# FLASH register map
Vendor: Texas Instruments
Peripheral module from a debugger description file (folder CC26x2x7).
Registers are 32-bit, read-only, reset 0x0 unless marked. A register's access mark holds for its fields unless they carry their own. Offsets are as the file gives them; lines under a group give offsets from that group; [hi:lo] are bit positions; {n}, {i} and the like mark numbered series; 'fields as' and 'values as' point back to an identical list; <NAME> marks a mode.

## FLASH — Flash sub-system registers, includes the Flash Memory Controller (FMC), flash read path, and an integrated Efuse controller and EFUSEROM.
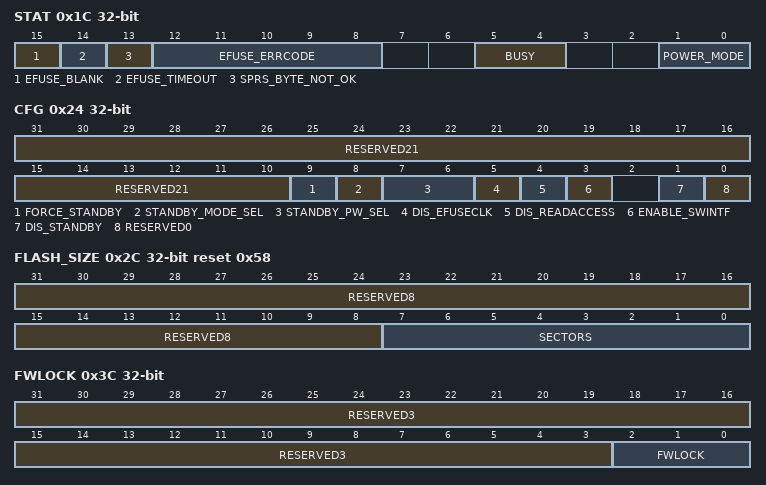
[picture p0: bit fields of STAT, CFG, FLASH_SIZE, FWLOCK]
0x1C STAT — FMC and Efuse Status
  [15] EFUSE_BLANK — Efuse scanning detected if fuse ROM is blank: 0 : Not blank 1 : Blank
  [14] EFUSE_TIMEOUT — Efuse scanning resulted in timeout error. 0 : No Timeout error 1 : Timeout Error
  [13] SPRS_BYTE_NOT_OK — Efuse scanning resulted in scan chain Sparse byte error. 0 : No Sparse error 1 : Sparse Error
  [12:8] EFUSE_ERRCODE — Same as EFUSEERROR.CODE
  [5:4] BUSY — Fast version of the FMC FMSTAT.BUSY bit. This flag is valid immediately after the operation setting it (FMSTAT.BUSY is delayed some cycles) 0 : Not busy 1 : Busy Bit 4 is for the busy state for Bank0 which is at logical address 0x0 Bit 5 for Bank1.
  [1:0] POWER_MODE — Power state of each of the 2 flash bank instances in the flash sub-system. 0 : Active 1 : Low power Bit 0 is for the power state for Bank0 which is at logical address 0x0 Bit 1 for Bank1
0x24 CFG access per field — Internal. Only to be used through TI provided API.
  [31:10] RESERVED21 rw — Internal. Only to be used through TI provided API.
  [9] FORCE_STANDBY rw — Internal. Only to be used through TI provided API.
  [8] STANDBY_MODE_SEL rw — Internal. Only to be used through TI provided API.
  [7:6] STANDBY_PW_SEL rw — Internal. Only to be used through TI provided API.
  [5] DIS_EFUSECLK rw — Internal. Only to be used through TI provided API.
  [4] DIS_READACCESS rw — Internal. Only to be used through TI provided API.
  [3] ENABLE_SWINTF rw — Internal. Only to be used through TI provided API.
  [1] DIS_STANDBY rw — Internal. Only to be used through TI provided API.
  [0] RESERVED0 ro — Internal. Only to be used through TI provided API.
0x2C FLASH_SIZE access per field reset 0x58 — Internal. Only to be used through TI provided API.
  [31:8] RESERVED8 ro — Internal. Only to be used through TI provided API.
  [7:0] SECTORS rw — Internal. Only to be used through TI provided API.
0x3C FWLOCK access per field — Internal. Only to be used through TI provided API.
  [31:3] RESERVED3 ro — Internal. Only to be used through TI provided API.
  [2:0] FWLOCK rw — Internal. Only to be used through TI provided API.
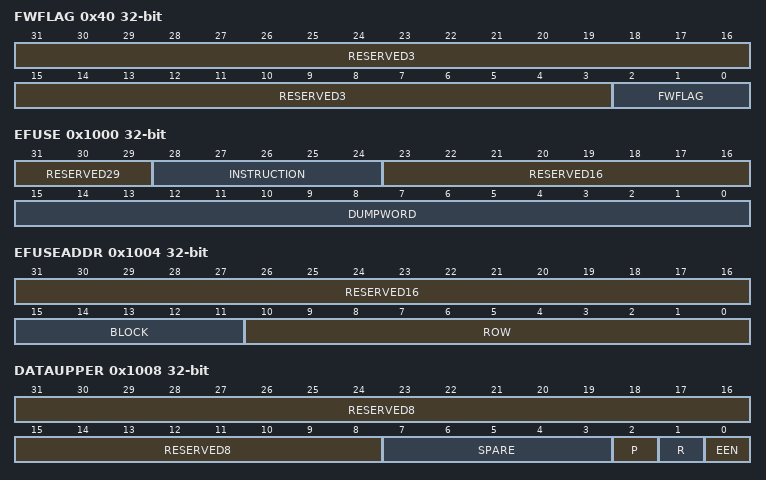
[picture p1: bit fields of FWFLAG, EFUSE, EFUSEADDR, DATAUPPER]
0x40 FWFLAG access per field — Internal. Only to be used through TI provided API.
  [31:3] RESERVED3 ro — Internal. Only to be used through TI provided API.
  [2:0] FWFLAG rw — Internal. Only to be used through TI provided API.
0x1000 EFUSE access per field — Internal. Only to be used through TI provided API.
  [31:29] RESERVED29 ro — Internal. Only to be used through TI provided API.
  [28:24] INSTRUCTION rw — Internal. Only to be used through TI provided API.
  [23:16] RESERVED16 ro — Internal. Only to be used through TI provided API.
  [15:0] DUMPWORD rw — Internal. Only to be used through TI provided API.
0x1004 EFUSEADDR access per field — Internal. Only to be used through TI provided API.
  [31:16] RESERVED16 ro — Internal. Only to be used through TI provided API.
  [15:11] BLOCK rw — Internal. Only to be used through TI provided API.
  [10:0] ROW rw — Internal. Only to be used through TI provided API.
0x1008 DATAUPPER access per field — Internal. Only to be used through TI provided API.
  [31:8] RESERVED8 ro — Internal. Only to be used through TI provided API.
  [7:3] SPARE rw — Internal. Only to be used through TI provided API.
  [2] P rw — Internal. Only to be used through TI provided API.
  [1] R rw — Internal. Only to be used through TI provided API.
  [0] EEN rw — Internal. Only to be used through TI provided API.
0x100C DATALOWER rw — Internal. Only to be used through TI provided API.
  [31:0] DATA
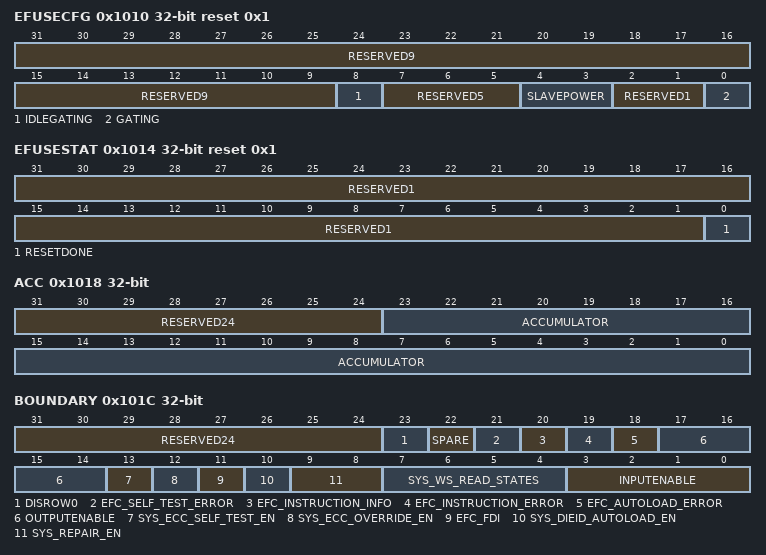
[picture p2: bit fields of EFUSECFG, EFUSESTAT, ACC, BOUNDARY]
0x1010 EFUSECFG access per field reset 0x1 — Internal. Only to be used through TI provided API.
  [31:9] RESERVED9 ro — Internal. Only to be used through TI provided API.
  [8] IDLEGATING rw — Internal. Only to be used through TI provided API.
  [7:5] RESERVED5 ro — Internal. Only to be used through TI provided API.
  [4:3] SLAVEPOWER rw — Internal. Only to be used through TI provided API.
  [2:1] RESERVED1 ro — Internal. Only to be used through TI provided API.
  [0] GATING rw — Internal. Only to be used through TI provided API.
0x1014 EFUSESTAT reset 0x1 — Internal. Only to be used through TI provided API.
  [31:1] RESERVED1 — Internal. Only to be used through TI provided API.
  [0] RESETDONE — Internal. Only to be used through TI provided API.
0x1018 ACC — Internal. Only to be used through TI provided API.
  [31:24] RESERVED24 — Internal. Only to be used through TI provided API.
  [23:0] ACCUMULATOR — Internal. Only to be used through TI provided API.
0x101C BOUNDARY access per field — Internal. Only to be used through TI provided API.
  [31:24] RESERVED24 ro — Internal. Only to be used through TI provided API.
  [23] DISROW0 rw — Internal. Only to be used through TI provided API.
  [22] SPARE rw — Internal. Only to be used through TI provided API.
  [21] EFC_SELF_TEST_ERROR rw — Internal. Only to be used through TI provided API.
  [20] EFC_INSTRUCTION_INFO rw — Internal. Only to be used through TI provided API.
  [19] EFC_INSTRUCTION_ERROR rw — Internal. Only to be used through TI provided API.
  [18] EFC_AUTOLOAD_ERROR rw — Internal. Only to be used through TI provided API.
  [17:14] OUTPUTENABLE rw — Internal. Only to be used through TI provided API.
  [13] SYS_ECC_SELF_TEST_EN rw — Internal. Only to be used through TI provided API.
  [12] SYS_ECC_OVERRIDE_EN rw — Internal. Only to be used through TI provided API.
  [11] EFC_FDI rw — Internal. Only to be used through TI provided API.
  [10] SYS_DIEID_AUTOLOAD_EN rw — Internal. Only to be used through TI provided API.
  [9:8] SYS_REPAIR_EN rw — Internal. Only to be used through TI provided API.
  [7:4] SYS_WS_READ_STATES rw — Internal. Only to be used through TI provided API.
  [3:0] INPUTENABLE rw — Internal. Only to be used through TI provided API.
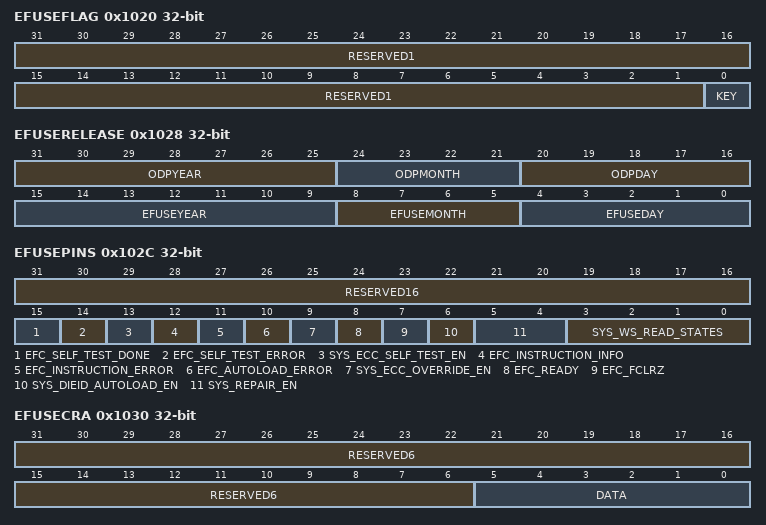
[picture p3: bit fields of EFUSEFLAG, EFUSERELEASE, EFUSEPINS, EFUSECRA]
0x1020 EFUSEFLAG — Internal. Only to be used through TI provided API.
  [31:1] RESERVED1 — Internal. Only to be used through TI provided API.
  [0] KEY — Internal. Only to be used through TI provided API.
0x1024 EFUSEKEY rw — Internal. Only to be used through TI provided API.
  [31:0] CODE
0x1028 EFUSERELEASE — Internal. Only to be used through TI provided API.
  [31:25] ODPYEAR — Internal. Only to be used through TI provided API.
  [24:21] ODPMONTH — Internal. Only to be used through TI provided API.
  [20:16] ODPDAY — Internal. Only to be used through TI provided API.
  [15:9] EFUSEYEAR — Internal. Only to be used through TI provided API.
  [8:5] EFUSEMONTH — Internal. Only to be used through TI provided API.
  [4:0] EFUSEDAY — Internal. Only to be used through TI provided API.
0x102C EFUSEPINS — Internal. Only to be used through TI provided API.
  [31:16] RESERVED16 — Internal. Only to be used through TI provided API.
  [15] EFC_SELF_TEST_DONE — Internal. Only to be used through TI provided API.
  [14] EFC_SELF_TEST_ERROR — Internal. Only to be used through TI provided API.
  [13] SYS_ECC_SELF_TEST_EN — Internal. Only to be used through TI provided API.
  [12] EFC_INSTRUCTION_INFO — Internal. Only to be used through TI provided API.
  [11] EFC_INSTRUCTION_ERROR — Internal. Only to be used through TI provided API.
  [10] EFC_AUTOLOAD_ERROR — Internal. Only to be used through TI provided API.
  [9] SYS_ECC_OVERRIDE_EN — Internal. Only to be used through TI provided API.
  [8] EFC_READY — Internal. Only to be used through TI provided API.
  [7] EFC_FCLRZ — Internal. Only to be used through TI provided API.
  [6] SYS_DIEID_AUTOLOAD_EN — Internal. Only to be used through TI provided API.
  [5:4] SYS_REPAIR_EN — Internal. Only to be used through TI provided API.
  [3:0] SYS_WS_READ_STATES — Internal. Only to be used through TI provided API.
0x1030 EFUSECRA access per field — Internal. Only to be used through TI provided API.
  [31:6] RESERVED6 ro — Internal. Only to be used through TI provided API.
  [5:0] DATA rw — Internal. Only to be used through TI provided API.
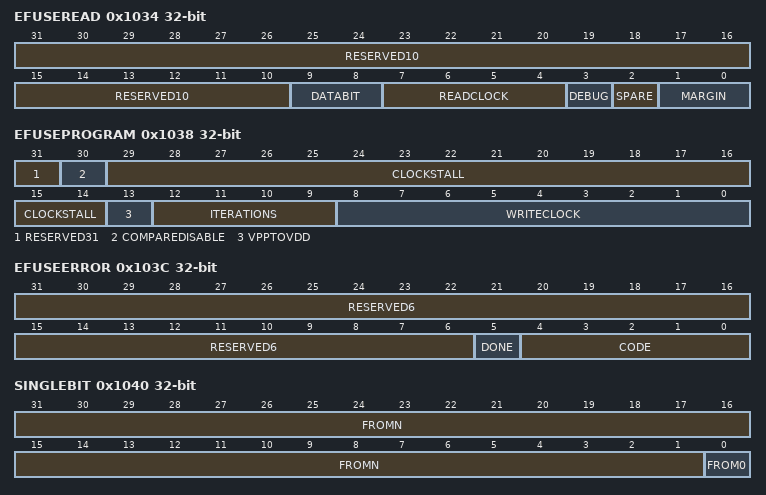
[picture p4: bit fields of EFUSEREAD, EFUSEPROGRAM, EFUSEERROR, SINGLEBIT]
0x1034 EFUSEREAD access per field — Internal. Only to be used through TI provided API.
  [31:10] RESERVED10 ro — Internal. Only to be used through TI provided API.
  [9:8] DATABIT rw — Internal. Only to be used through TI provided API.
  [7:4] READCLOCK rw — Internal. Only to be used through TI provided API.
  [3] DEBUG rw — Internal. Only to be used through TI provided API.
  [2] SPARE rw — Internal. Only to be used through TI provided API.
  [1:0] MARGIN rw — Internal. Only to be used through TI provided API.
0x1038 EFUSEPROGRAM access per field — Internal. Only to be used through TI provided API.
  [31] RESERVED31 ro — Internal. Only to be used through TI provided API.
  [30] COMPAREDISABLE rw — Internal. Only to be used through TI provided API.
  [29:14] CLOCKSTALL rw — Internal. Only to be used through TI provided API.
  [13] VPPTOVDD rw — Internal. Only to be used through TI provided API.
  [12:9] ITERATIONS rw — Internal. Only to be used through TI provided API.
  [8:0] WRITECLOCK rw — Internal. Only to be used through TI provided API.
0x103C EFUSEERROR access per field — Internal. Only to be used through TI provided API.
  [31:6] RESERVED6 ro — Internal. Only to be used through TI provided API.
  [5] DONE rw — Internal. Only to be used through TI provided API.
  [4:0] CODE rw — Internal. Only to be used through TI provided API.
0x1040 SINGLEBIT — Internal. Only to be used through TI provided API.
  [31:1] FROMN — Internal. Only to be used through TI provided API.
  [0] FROM0 — Internal. Only to be used through TI provided API.
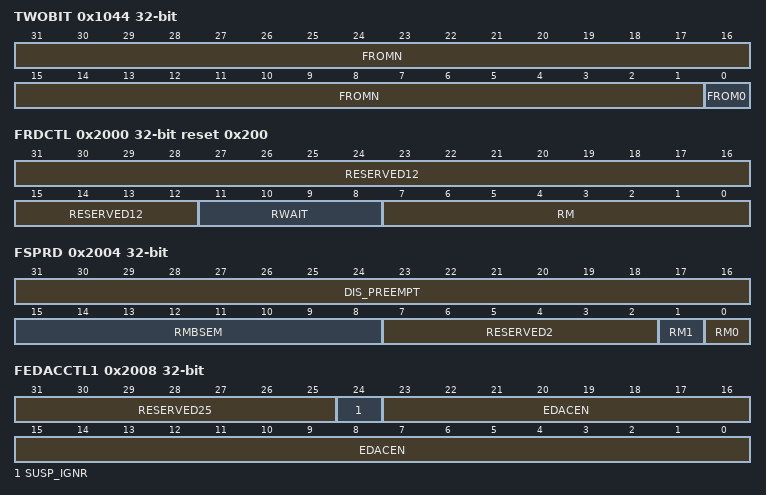
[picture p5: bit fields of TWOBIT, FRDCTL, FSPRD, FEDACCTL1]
0x1044 TWOBIT — Internal. Only to be used through TI provided API.
  fields as SINGLEBIT
0x1048 SELFTESTCYC rw — Internal. Only to be used through TI provided API.
  [31:0] CYCLES
0x104C SELFTESTSIGN rw — Internal. Only to be used through TI provided API.
  [31:0] SIGNATURE
0x2000 FRDCTL access per field reset 0x200 — Internal. Only to be used through TI provided API.
  [31:12] RESERVED12 ro — Internal. Only to be used through TI provided API.
  [11:8] RWAIT rw — Internal. Only to be used through TI provided API.
  [7:0] RM ro — Internal. Only to be used through TI provided API.
0x2004 FSPRD access per field — Internal. Only to be used through TI provided API.
  [31:16] DIS_PREEMPT ro — Internal. Only to be used through TI provided API.
  [15:8] RMBSEM rw — Internal. Only to be used through TI provided API.
  [7:2] RESERVED2 ro — Internal. Only to be used through TI provided API.
  [1] RM1 rw — Internal. Only to be used through TI provided API.
  [0] RM0 rw — Internal. Only to be used through TI provided API.
0x2008 FEDACCTL1 access per field — Internal. Only to be used through TI provided API.
  [31:25] RESERVED25 ro — Internal. Only to be used through TI provided API.
  [24] SUSP_IGNR rw — Internal. Only to be used through TI provided API.
  [23:0] EDACEN ro — Internal. Only to be used through TI provided API.
0x200C FEDACCTL2 — Internal. Only to be used through TI provided API.
  [31:0] SEC_THRESHOLD
0x2010 FCOR_ERR_CNT — Internal. Only to be used through TI provided API.
  [31:0] COR_ERR_CNT
0x2014 FCOR_ERR_ADD — Internal. Only to be used through TI provided API.
0x2018 FCOR_ERR_POS — Internal. Only to be used through TI provided API.
  [31:0] SERR_POS
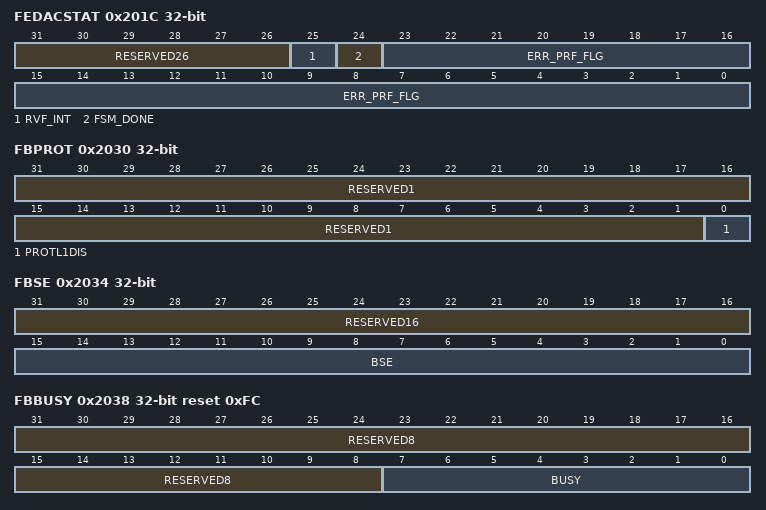
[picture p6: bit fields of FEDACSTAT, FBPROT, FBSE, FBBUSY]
0x201C FEDACSTAT access per field — Internal. Only to be used through TI provided API.
  [31:26] RESERVED26 ro — Internal. Only to be used through TI provided API.
  [25] RVF_INT rw — Internal. Only to be used through TI provided API.
  [24] FSM_DONE rw — Internal. Only to be used through TI provided API.
  [23:0] ERR_PRF_FLG ro — Internal. Only to be used through TI provided API.
0x2020 FUNC_ERR_ADD — Internal. Only to be used through TI provided API.
0x2024 FEDACSDIS — Internal. Only to be used through TI provided API.
  [31:0] SECTORID0
0x2028 FPRIM_ADD_TAG — Internal. Only to be used through TI provided API.
  [31:0] PRIM_ADD_TAG
0x202C FREDU_ADD_TAG — Internal. Only to be used through TI provided API.
  [31:0] REDU_ADD_TAG
0x2030 FBPROT access per field — Internal. Only to be used through TI provided API.
  [31:1] RESERVED1 ro — Internal. Only to be used through TI provided API.
  [0] PROTL1DIS rw — Internal. Only to be used through TI provided API.
0x2034 FBSE access per field — Internal. Only to be used through TI provided API.
  [31:16] RESERVED16 ro — Internal. Only to be used through TI provided API.
  [15:0] BSE rw — Internal. Only to be used through TI provided API.
0x2038 FBBUSY reset 0xFC — Internal. Only to be used through TI provided API.
  [31:8] RESERVED8 — Internal. Only to be used through TI provided API.
  [7:0] BUSY — Internal. Only to be used through TI provided API.
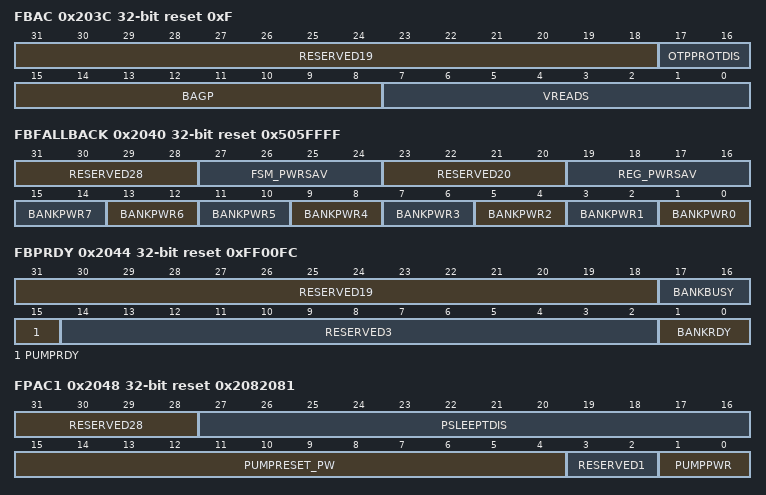
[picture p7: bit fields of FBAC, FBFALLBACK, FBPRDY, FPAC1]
0x203C FBAC access per field reset 0xF — Internal. Only to be used through TI provided API.
  [31:18] RESERVED19 ro — Internal. Only to be used through TI provided API.
  [17:16] OTPPROTDIS rw — Internal. Only to be used through TI provided API.
  [15:8] BAGP rw — Internal. Only to be used through TI provided API.
  [7:0] VREADS rw — Internal. Only to be used through TI provided API.
0x2040 FBFALLBACK access per field reset 0x505FFFF — Internal. Only to be used through TI provided API.
  [31:28] RESERVED28 ro — Internal. Only to be used through TI provided API.
  [27:24] FSM_PWRSAV rw — Internal. Only to be used through TI provided API.
  [23:20] RESERVED20 ro — Internal. Only to be used through TI provided API.
  [19:16] REG_PWRSAV rw — Internal. Only to be used through TI provided API.
  [2n+1:2n] BANKPWR{n} rw (n=0..7) — Internal. Only to be used through TI provided API.
0x2044 FBPRDY reset 0xFF00FC — Internal. Only to be used through TI provided API.
  [31:18] RESERVED19 — Internal. Only to be used through TI provided API.
  [17:16] BANKBUSY — Internal. Only to be used through TI provided API.
  [15] PUMPRDY — Internal. Only to be used through TI provided API.
  [14:2] RESERVED3 — Internal. Only to be used through TI provided API.
  [1:0] BANKRDY — Internal. Only to be used through TI provided API.
0x2048 FPAC1 access per field reset 0x2082081 — Internal. Only to be used through TI provided API.
  [31:28] RESERVED28 ro — Internal. Only to be used through TI provided API.
  [27:16] PSLEEPTDIS rw — Internal. Only to be used through TI provided API.
  [15:4] PUMPRESET_PW rw — Internal. Only to be used through TI provided API.
  [3:2] RESERVED1 ro — Internal. Only to be used through TI provided API.
  [1:0] PUMPPWR rw — Internal. Only to be used through TI provided API.
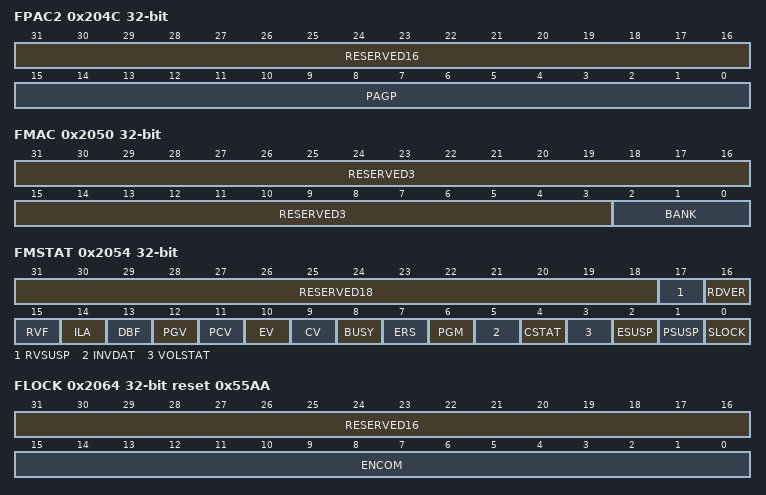
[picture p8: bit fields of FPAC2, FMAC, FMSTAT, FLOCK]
0x204C FPAC2 access per field — Internal. Only to be used through TI provided API.
  [31:16] RESERVED16 ro — Internal. Only to be used through TI provided API.
  [15:0] PAGP rw — Internal. Only to be used through TI provided API.
0x2050 FMAC access per field — Internal. Only to be used through TI provided API.
  [31:3] RESERVED3 ro — Internal. Only to be used through TI provided API.
  [2:0] BANK rw — Internal. Only to be used through TI provided API.
0x2054 FMSTAT — Internal. Only to be used through TI provided API.
  [31:18] RESERVED18 — Internal. Only to be used through TI provided API.
  [17] RVSUSP — Internal. Only to be used through TI provided API.
  [16] RDVER — Internal. Only to be used through TI provided API.
  [15] RVF — Internal. Only to be used through TI provided API.
  [14] ILA — Internal. Only to be used through TI provided API.
  [13] DBF — Internal. Only to be used through TI provided API.
  [12] PGV — Internal. Only to be used through TI provided API.
  [11] PCV — Internal. Only to be used through TI provided API.
  [10] EV — Internal. Only to be used through TI provided API.
  [9] CV — Internal. Only to be used through TI provided API.
  [8] BUSY — Internal. Only to be used through TI provided API.
  [7] ERS — Internal. Only to be used through TI provided API.
  [6] PGM — Internal. Only to be used through TI provided API.
  [5] INVDAT — Internal. Only to be used through TI provided API.
  [4] CSTAT — Internal. Only to be used through TI provided API.
  [3] VOLSTAT — Internal. Only to be used through TI provided API.
  [2] ESUSP — Internal. Only to be used through TI provided API.
  [1] PSUSP — Internal. Only to be used through TI provided API.
  [0] SLOCK — Internal. Only to be used through TI provided API.
0x2058 FEMU_DMSW rw — Internal. Only to be used through TI provided API.
0x205C FEMU_DLSW rw — Internal. Only to be used through TI provided API.
0x2060 FEMU_ECC rw — Internal. Only to be used through TI provided API.
  [31:0] EMU_ECC
0x2064 FLOCK access per field reset 0x55AA — Internal. Only to be used through TI provided API.
  [31:16] RESERVED16 ro — Internal. Only to be used through TI provided API.
  [15:0] ENCOM rw — Internal. Only to be used through TI provided API.
0x2068 FEMU_ADDR rw — Internal. Only to be used through TI provided API.
  [31:0] EMU_ADDR
0x206C FDIAGCTL rw — Internal. Only to be used through TI provided API.
  [31:0] DIAGMODE
0x2070 FRAW_DATAH rw — Internal. Only to be used through TI provided API.
0x2074 FRAW_DATAL rw — Internal. Only to be used through TI provided API.
0x2078 FRAW_ECC rw — Internal. Only to be used through TI provided API.
  [31:0] RAW_ECC
0x207C FPAR_OVR rw — Internal. Only to be used through TI provided API.
  [31:0] DAT_INV_PAR
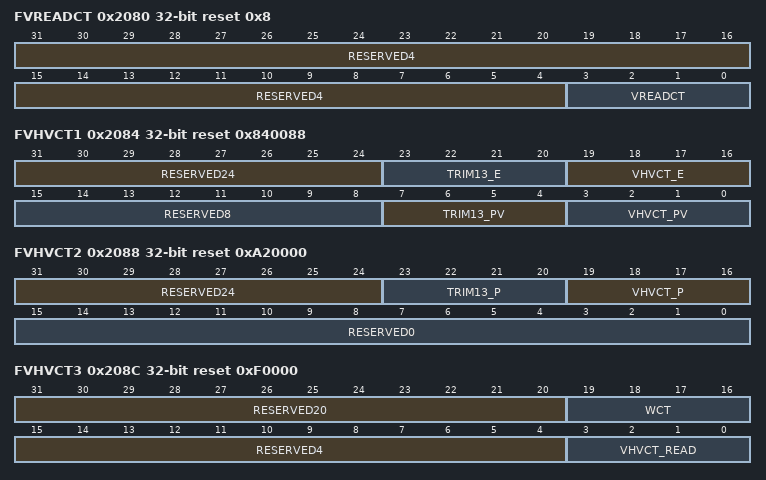
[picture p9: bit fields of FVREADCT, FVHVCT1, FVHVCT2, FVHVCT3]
0x2080 FVREADCT access per field reset 0x8 — Internal. Only to be used through TI provided API.
  [31:4] RESERVED4 ro — Internal. Only to be used through TI provided API.
  [3:0] VREADCT rw — Internal. Only to be used through TI provided API.
0x2084 FVHVCT1 access per field reset 0x840088 — Internal. Only to be used through TI provided API.
  [31:24] RESERVED24 ro — Internal. Only to be used through TI provided API.
  [23:20] TRIM13_E rw — Internal. Only to be used through TI provided API.
  [19:16] VHVCT_E rw — Internal. Only to be used through TI provided API.
  [15:8] RESERVED8 ro — Internal. Only to be used through TI provided API.
  [7:4] TRIM13_PV rw — Internal. Only to be used through TI provided API.
  [3:0] VHVCT_PV rw — Internal. Only to be used through TI provided API.
0x2088 FVHVCT2 access per field reset 0xA20000 — Internal. Only to be used through TI provided API.
  [31:24] RESERVED24 ro — Internal. Only to be used through TI provided API.
  [23:20] TRIM13_P rw — Internal. Only to be used through TI provided API.
  [19:16] VHVCT_P rw — Internal. Only to be used through TI provided API.
  [15:0] RESERVED0 ro — Internal. Only to be used through TI provided API.
0x208C FVHVCT3 access per field reset 0xF0000 — Internal. Only to be used through TI provided API.
  [31:20] RESERVED20 ro — Internal. Only to be used through TI provided API.
  [19:16] WCT rw — Internal. Only to be used through TI provided API.
  [15:4] RESERVED4 ro — Internal. Only to be used through TI provided API.
  [3:0] VHVCT_READ rw — Internal. Only to be used through TI provided API.
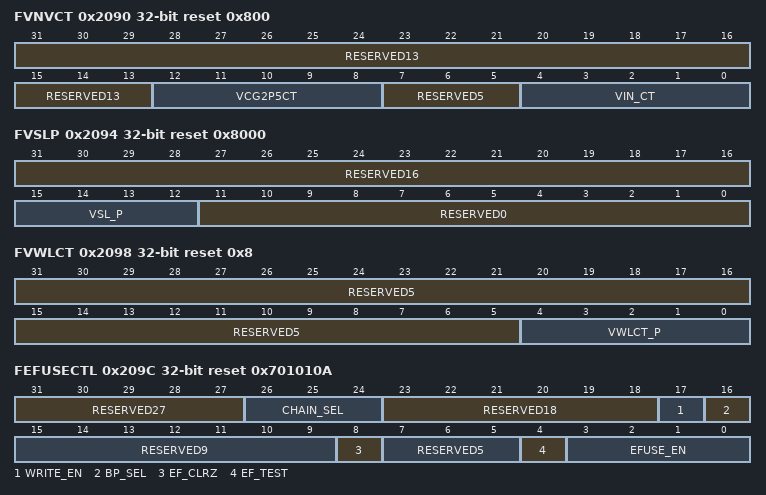
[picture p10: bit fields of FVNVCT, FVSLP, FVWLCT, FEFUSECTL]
0x2090 FVNVCT access per field reset 0x800 — Internal. Only to be used through TI provided API.
  [31:13] RESERVED13 ro — Internal. Only to be used through TI provided API.
  [12:8] VCG2P5CT rw — Internal. Only to be used through TI provided API.
  [7:5] RESERVED5 ro — Internal. Only to be used through TI provided API.
  [4:0] VIN_CT rw — Internal. Only to be used through TI provided API.
0x2094 FVSLP access per field reset 0x8000 — Internal. Only to be used through TI provided API.
  [31:16] RESERVED16 ro — Internal. Only to be used through TI provided API.
  [15:12] VSL_P rw — Internal. Only to be used through TI provided API.
  [11:0] RESERVED0 ro — Internal. Only to be used through TI provided API.
0x2098 FVWLCT access per field reset 0x8 — Internal. Only to be used through TI provided API.
  [31:5] RESERVED5 ro — Internal. Only to be used through TI provided API.
  [4:0] VWLCT_P rw — Internal. Only to be used through TI provided API.
0x209C FEFUSECTL access per field reset 0x701010A — Internal. Only to be used through TI provided API.
  [31:27] RESERVED27 ro — Internal. Only to be used through TI provided API.
  [26:24] CHAIN_SEL rw — Internal. Only to be used through TI provided API.
  [23:18] RESERVED18 ro — Internal. Only to be used through TI provided API.
  [17] WRITE_EN rw — Internal. Only to be used through TI provided API.
  [16] BP_SEL rw — Internal. Only to be used through TI provided API.
  [15:9] RESERVED9 ro — Internal. Only to be used through TI provided API.
  [8] EF_CLRZ rw — Internal. Only to be used through TI provided API.
  [7:5] RESERVED5 ro — Internal. Only to be used through TI provided API.
  [4] EF_TEST rw — Internal. Only to be used through TI provided API.
  [3:0] EFUSE_EN rw — Internal. Only to be used through TI provided API.
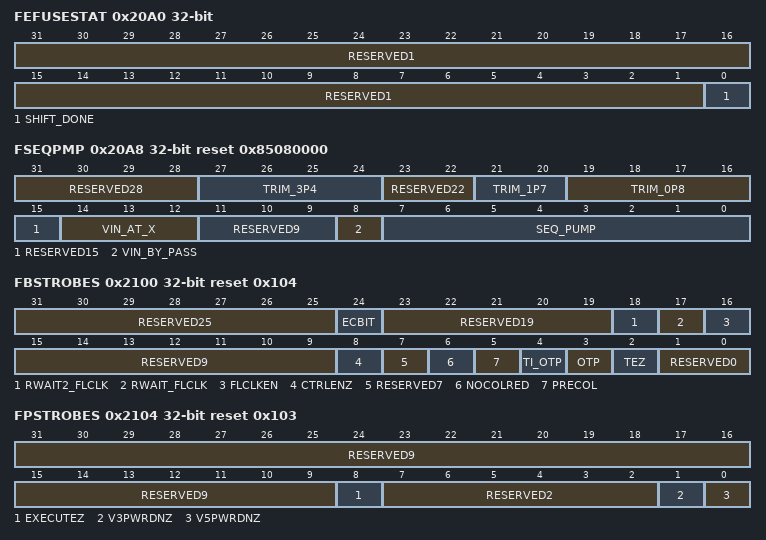
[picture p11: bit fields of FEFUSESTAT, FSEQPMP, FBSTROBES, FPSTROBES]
0x20A0 FEFUSESTAT access per field — Internal. Only to be used through TI provided API.
  [31:1] RESERVED1 ro — Internal. Only to be used through TI provided API.
  [0] SHIFT_DONE rw — Internal. Only to be used through TI provided API.
0x20A4 FEFUSEDATA rw — Internal. Only to be used through TI provided API.
0x20A8 FSEQPMP access per field reset 0x85080000 — Internal. Only to be used through TI provided API.
  [31:28] RESERVED28 rw — Internal. Only to be used through TI provided API.
  [27:24] TRIM_3P4 rw — Internal. Only to be used through TI provided API.
  [23:22] RESERVED22 ro — Internal. Only to be used through TI provided API.
  [21:20] TRIM_1P7 rw — Internal. Only to be used through TI provided API.
  [19:16] TRIM_0P8 rw — Internal. Only to be used through TI provided API.
  [15] RESERVED15 ro — Internal. Only to be used through TI provided API.
  [14:12] VIN_AT_X rw — Internal. Only to be used through TI provided API.
  [11:9] RESERVED9 ro — Internal. Only to be used through TI provided API.
  [8] VIN_BY_PASS rw — Internal. Only to be used through TI provided API.
  [7:0] SEQ_PUMP rw — Internal. Only to be used through TI provided API.
0x20AC FCLKTRIM rw — Internal. Only to be used through TI provided API.
  [31:0] TRIM_EN
0x20B0 ROM_TEST rw — Internal. Only to be used through TI provided API.
  [31:0] ROM_KEY
0x20C0 FEDACSDIS2 rw — Internal. Only to be used through TI provided API.
  [31:0] SECTORID2
0x2100 FBSTROBES access per field reset 0x104 — Internal. Only to be used through TI provided API.
  [31:25] RESERVED25 ro — Internal. Only to be used through TI provided API.
  [24] ECBIT rw — Internal. Only to be used through TI provided API.
  [23:19] RESERVED19 ro — Internal. Only to be used through TI provided API.
  [18] RWAIT2_FLCLK rw — Internal. Only to be used through TI provided API.
  [17] RWAIT_FLCLK rw — Internal. Only to be used through TI provided API.
  [16] FLCLKEN rw — Internal. Only to be used through TI provided API.
  [15:9] RESERVED9 ro — Internal. Only to be used through TI provided API.
  [8] CTRLENZ rw — Internal. Only to be used through TI provided API.
  [7] RESERVED7 ro — Internal. Only to be used through TI provided API.
  [6] NOCOLRED rw — Internal. Only to be used through TI provided API.
  [5] PRECOL rw — Internal. Only to be used through TI provided API.
  [4] TI_OTP rw — Internal. Only to be used through TI provided API.
  [3] OTP rw — Internal. Only to be used through TI provided API.
  [2] TEZ rw — Internal. Only to be used through TI provided API.
  [1:0] RESERVED0 ro — Internal. Only to be used through TI provided API.
0x2104 FPSTROBES access per field reset 0x103 — Internal. Only to be used through TI provided API.
  [31:9] RESERVED9 ro — Internal. Only to be used through TI provided API.
  [8] EXECUTEZ rw — Internal. Only to be used through TI provided API.
  [7:2] RESERVED2 ro — Internal. Only to be used through TI provided API.
  [1] V3PWRDNZ rw — Internal. Only to be used through TI provided API.
  [0] V5PWRDNZ rw — Internal. Only to be used through TI provided API.
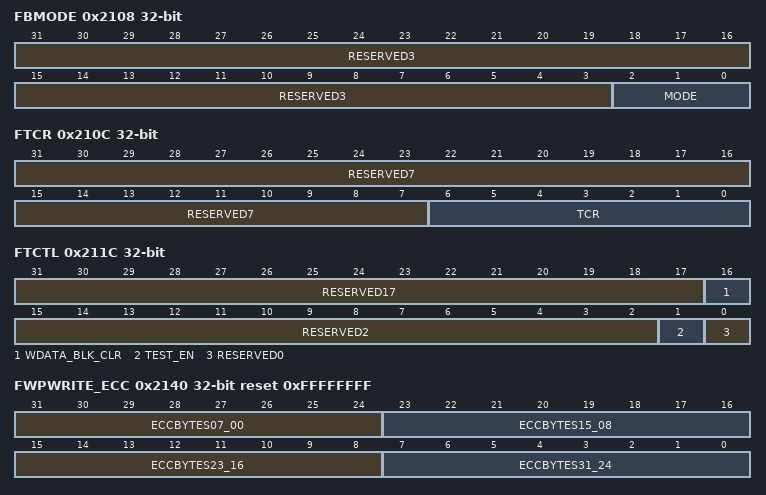
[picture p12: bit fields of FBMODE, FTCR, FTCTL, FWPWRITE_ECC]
0x2108 FBMODE access per field — Internal. Only to be used through TI provided API.
  [31:3] RESERVED3 ro — Internal. Only to be used through TI provided API.
  [2:0] MODE rw — Internal. Only to be used through TI provided API.
0x210C FTCR access per field — Internal. Only to be used through TI provided API.
  [31:7] RESERVED7 ro — Internal. Only to be used through TI provided API.
  [6:0] TCR rw — Internal. Only to be used through TI provided API.
0x2110 FADDR rw — Internal. Only to be used through TI provided API.
0x2114 FPMTCTL — Internal. Only to be used through TI provided API.
  [31:0] ADDR_INCR
0x2118 PBISTCTL — Internal. Only to be used through TI provided API.
  [31:0] PBIST_KEY
0x211C FTCTL access per field — Internal. Only to be used through TI provided API.
  [31:17] RESERVED17 ro — Internal. Only to be used through TI provided API.
  [16] WDATA_BLK_CLR rw — Internal. Only to be used through TI provided API.
  [15:2] RESERVED2 ro — Internal. Only to be used through TI provided API.
  [1] TEST_EN rw — Internal. Only to be used through TI provided API.
  [0] RESERVED0 ro — Internal. Only to be used through TI provided API.
{0x2120+4i} FWPWRITE{i} rw reset 0xFFFFFFFF (i=0..7) — Internal. Only to be used through TI provided API.
0x2140 FWPWRITE_ECC rw reset 0xFFFFFFFF — Internal. Only to be used through TI provided API.
  [31:24] ECCBYTES07_00 — Internal. Only to be used through TI provided API.
  [23:16] ECCBYTES15_08 — Internal. Only to be used through TI provided API.
  [15:8] ECCBYTES23_16 — Internal. Only to be used through TI provided API.
  [7:0] ECCBYTES31_24 — Internal. Only to be used through TI provided API.
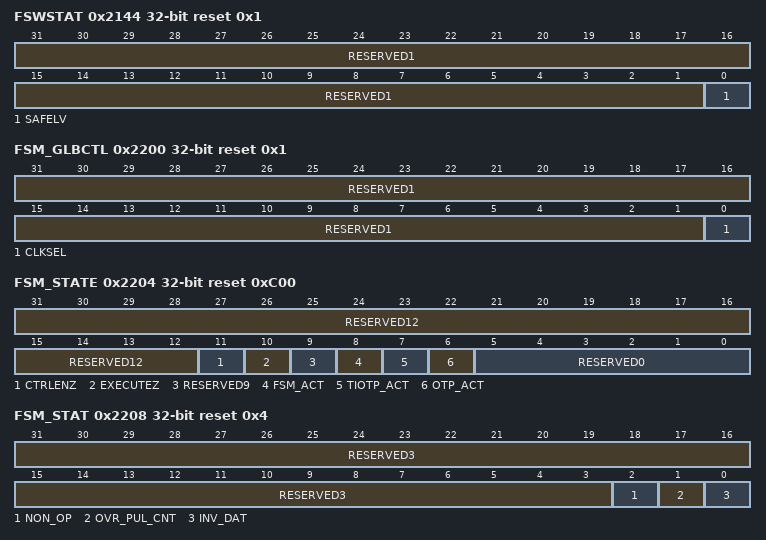
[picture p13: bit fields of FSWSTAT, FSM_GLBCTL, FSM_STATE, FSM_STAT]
0x2144 FSWSTAT reset 0x1 — Internal. Only to be used through TI provided API.
  [31:1] RESERVED1 — Internal. Only to be used through TI provided API.
  [0] SAFELV — Internal. Only to be used through TI provided API.
0x2200 FSM_GLBCTL reset 0x1 — Internal. Only to be used through TI provided API.
  [31:1] RESERVED1 — Internal. Only to be used through TI provided API.
  [0] CLKSEL — Internal. Only to be used through TI provided API.
0x2204 FSM_STATE reset 0xC00 — Internal. Only to be used through TI provided API.
  [31:12] RESERVED12 — Internal. Only to be used through TI provided API.
  [11] CTRLENZ — Internal. Only to be used through TI provided API.
  [10] EXECUTEZ — Internal. Only to be used through TI provided API.
  [9] RESERVED9 — Internal. Only to be used through TI provided API.
  [8] FSM_ACT — Internal. Only to be used through TI provided API.
  [7] TIOTP_ACT — Internal. Only to be used through TI provided API.
  [6] OTP_ACT — Internal. Only to be used through TI provided API.
  [5:0] RESERVED0 — Internal. Only to be used through TI provided API.
0x2208 FSM_STAT reset 0x4 — Internal. Only to be used through TI provided API.
  [31:3] RESERVED3 — Internal. Only to be used through TI provided API.
  [2] NON_OP — Internal. Only to be used through TI provided API.
  [1] OVR_PUL_CNT — Internal. Only to be used through TI provided API.
  [0] INV_DAT — Internal. Only to be used through TI provided API.
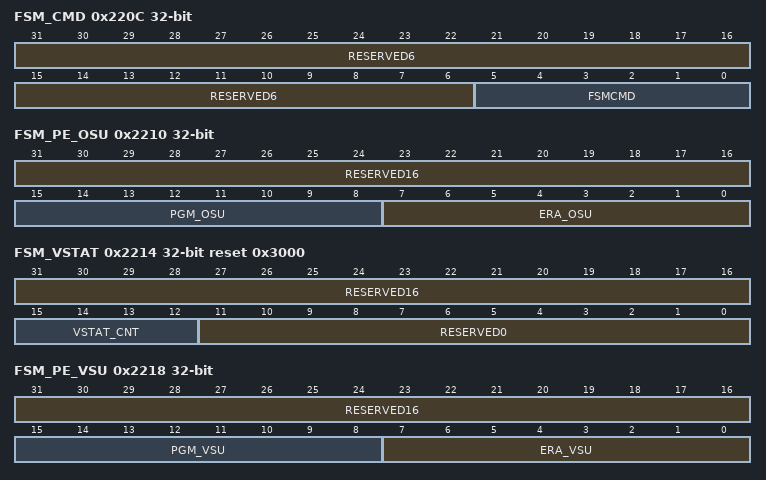
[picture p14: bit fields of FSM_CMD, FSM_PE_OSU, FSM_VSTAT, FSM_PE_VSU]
0x220C FSM_CMD access per field — Internal. Only to be used through TI provided API.
  [31:6] RESERVED6 ro — Internal. Only to be used through TI provided API.
  [5:0] FSMCMD rw — Internal. Only to be used through TI provided API.
0x2210 FSM_PE_OSU access per field — Internal. Only to be used through TI provided API.
  [31:16] RESERVED16 ro — Internal. Only to be used through TI provided API.
  [15:8] PGM_OSU rw — Internal. Only to be used through TI provided API.
  [7:0] ERA_OSU rw — Internal. Only to be used through TI provided API.
0x2214 FSM_VSTAT access per field reset 0x3000 — Internal. Only to be used through TI provided API.
  [31:16] RESERVED16 ro — Internal. Only to be used through TI provided API.
  [15:12] VSTAT_CNT rw — Internal. Only to be used through TI provided API.
  [11:0] RESERVED0 ro — Internal. Only to be used through TI provided API.
0x2218 FSM_PE_VSU access per field — Internal. Only to be used through TI provided API.
  [31:16] RESERVED16 ro — Internal. Only to be used through TI provided API.
  [15:8] PGM_VSU rw — Internal. Only to be used through TI provided API.
  [7:0] ERA_VSU rw — Internal. Only to be used through TI provided API.
0x221C FSM_CMP_VSU access per field — Internal. Only to be used through TI provided API.
  [31:16] RESERVED16 ro — Internal. Only to be used through TI provided API.
  [15:12] ADD_EXZ rw — Internal. Only to be used through TI provided API.
  [11:0] RESERVED0 ro — Internal. Only to be used through TI provided API.
0x2220 FSM_EX_VAL access per field reset 0x301 — Internal. Only to be used through TI provided API.
  [31:16] RESERVED16 ro — Internal. Only to be used through TI provided API.
  [15:8] REP_VSU rw — Internal. Only to be used through TI provided API.
  [7:0] EXE_VALD rw — Internal. Only to be used through TI provided API.
0x2224 FSM_RD_H access per field reset 0x5A — Internal. Only to be used through TI provided API.
  [31:8] RESERVED8 ro — Internal. Only to be used through TI provided API.
  [7:0] RD_H rw — Internal. Only to be used through TI provided API.
0x2228 FSM_P_OH access per field reset 0x100 — Internal. Only to be used through TI provided API.
  [31:16] RESERVED16 ro — Internal. Only to be used through TI provided API.
  [15:8] PGM_OH rw — Internal. Only to be used through TI provided API.
  [7:0] RESERVED0 ro — Internal. Only to be used through TI provided API.
0x222C FSM_ERA_OH access per field reset 0x1 — Internal. Only to be used through TI provided API.
  [31:16] RESERVED16 ro — Internal. Only to be used through TI provided API.
  [15:0] ERA_OH rw — Internal. Only to be used through TI provided API.
0x2230 FSM_SAV_PPUL — Internal. Only to be used through TI provided API.
  [31:12] RESERVED12 — Internal. Only to be used through TI provided API.
  [11:0] SAV_P_PUL — Internal. Only to be used through TI provided API.
0x2234 FSM_PE_VH access per field reset 0x100 — Internal. Only to be used through TI provided API.
  [31:16] RESERVED16 ro — Internal. Only to be used through TI provided API.
  [15:8] PGM_VH rw — Internal. Only to be used through TI provided API.
  [7:0] ERA_VH ro — Internal. Only to be used through TI provided API.
0x2240 FSM_PRG_PW access per field — Internal. Only to be used through TI provided API.
  [31:16] RESERVED16 ro — Internal. Only to be used through TI provided API.
  [15:0] PROG_PUL_WIDTH rw — Internal. Only to be used through TI provided API.
0x2244 FSM_ERA_PW rw — Internal. Only to be used through TI provided API.
0x2254 FSM_SAV_ERA_PUL — Internal. Only to be used through TI provided API.
  [31:12] RESERVED12 — Internal. Only to be used through TI provided API.
  [11:0] SAV_ERA_PUL — Internal. Only to be used through TI provided API.
0x2258 FSM_TIMER — Internal. Only to be used through TI provided API.
0x225C FSM_MODE — Internal. Only to be used through TI provided API.
  [31:20] RESERVED20 — Internal. Only to be used through TI provided API.
  [19:18] RDV_SUBMODE — Internal. Only to be used through TI provided API.
  [17:16] PGM_SUBMODE — Internal. Only to be used through TI provided API.
  [15:14] ERA_SUBMODE — Internal. Only to be used through TI provided API.
  [13:12] SUBMODE — Internal. Only to be used through TI provided API.
  [11:9] SAV_PGM_CMD — Internal. Only to be used through TI provided API.
  [8:6] SAV_ERA_MODE — Internal. Only to be used through TI provided API.
  [5:3] MODE — Internal. Only to be used through TI provided API.
  [2:0] CMD — Internal. Only to be used through TI provided API.
0x2260 FSM_PGM — Internal. Only to be used through TI provided API.
  [31:26] RESERVED26 — Internal. Only to be used through TI provided API.
  [25:23] PGM_BANK — Internal. Only to be used through TI provided API.
  [22:0] PGM_ADDR — Internal. Only to be used through TI provided API.
0x2264 FSM_ERA — Internal. Only to be used through TI provided API.
  [31:26] RESERVED26 — Internal. Only to be used through TI provided API.
  [25:23] ERA_BANK — Internal. Only to be used through TI provided API.
  [22:0] ERA_ADDR — Internal. Only to be used through TI provided API.
0x2268 FSM_PRG_PUL access per field reset 0x40032 — Internal. Only to be used through TI provided API.
  [31:20] RESERVED20 ro — Internal. Only to be used through TI provided API.
  [19:16] BEG_EC_LEVEL rw — Internal. Only to be used through TI provided API.
  [15:12] RESERVED12 ro — Internal. Only to be used through TI provided API.
  [11:0] MAX_PRG_PUL rw — Internal. Only to be used through TI provided API.
0x226C FSM_ERA_PUL access per field reset 0x40BB8 — Internal. Only to be used through TI provided API.
  [31:20] RESERVED20 ro — Internal. Only to be used through TI provided API.
  [19:16] MAX_EC_LEVEL rw — Internal. Only to be used through TI provided API.
  [15:12] RESERVED12 ro — Internal. Only to be used through TI provided API.
  [11:0] MAX_ERA_PUL rw — Internal. Only to be used through TI provided API.
0x2270 FSM_STEP_SIZE access per field — Internal. Only to be used through TI provided API.
  [31:25] RESERVED25 ro — Internal. Only to be used through TI provided API.
  [24:16] EC_STEP_SIZE rw — Internal. Only to be used through TI provided API.
  [15:0] RESERVED0 ro — Internal. Only to be used through TI provided API.
0x2274 FSM_PUL_CNTR — Internal. Only to be used through TI provided API.
  [31:25] RESERVED25 — Internal. Only to be used through TI provided API.
  [24:16] CUR_EC_LEVEL — Internal. Only to be used through TI provided API.
  [15:12] RESERVED12 — Internal. Only to be used through TI provided API.
  [11:0] PUL_CNTR — Internal. Only to be used through TI provided API.
0x2278 FSM_EC_STEP_HEIGHT access per field — Internal. Only to be used through TI provided API.
  [31:4] RESERVED4 ro — Internal. Only to be used through TI provided API.
  [3:0] EC_STEP_HEIGHT rw — Internal. Only to be used through TI provided API.
0x227C FSM_ST_MACHINE access per field reset 0x800500 — Internal. Only to be used through TI provided API.
  [31:24] RESERVED24 ro — Internal. Only to be used through TI provided API.
  [23] DO_PRECOND rw — Internal. Only to be used through TI provided API.
  [22] FSM_INT_EN rw — Internal. Only to be used through TI provided API.
  [21] ALL_BANKS rw — Internal. Only to be used through TI provided API.
  [20] CMPV_ALLOWED rw — Internal. Only to be used through TI provided API.
  [19] RANDOM rw — Internal. Only to be used through TI provided API.
  [18] RV_SEC_EN rw — Internal. Only to be used through TI provided API.
  [17] RV_RES rw — Internal. Only to be used through TI provided API.
  [16] RV_INT_EN rw — Internal. Only to be used through TI provided API.
  [15] RESERVED15 ro — Internal. Only to be used through TI provided API.
  [14] ONE_TIME_GOOD rw — Internal. Only to be used through TI provided API.
  [13:12] RESERVED12 ro — Internal. Only to be used through TI provided API.
  [11] DO_REDU_COL rw — Internal. Only to be used through TI provided API.
  [10:7] DBG_SHORT_ROW rw — Internal. Only to be used through TI provided API.
  [6] RESERVED6 ro — Internal. Only to be used through TI provided API.
  [5] PGM_SEC_COF_EN rw — Internal. Only to be used through TI provided API.
  [4] PREC_STOP_EN rw — Internal. Only to be used through TI provided API.
  [3] DIS_TST_EN rw — Internal. Only to be used through TI provided API.
  [2] CMD_EN rw — Internal. Only to be used through TI provided API.
  [1] INV_DATA rw — Internal. Only to be used through TI provided API.
  [0] OVERRIDE rw — Internal. Only to be used through TI provided API.
0x2280 FSM_FLES access per field — Internal. Only to be used through TI provided API.
  [31:12] RESERVED12 ro — Internal. Only to be used through TI provided API.
  [11:8] BLK_TIOTP rw — Internal. Only to be used through TI provided API.
  [7:0] BLK_OTP rw — Internal. Only to be used through TI provided API.
0x2288 FSM_WR_ENA access per field reset 0x2 — Internal. Only to be used through TI provided API.
  [31:3] RESERVED3 ro — Internal. Only to be used through TI provided API.
  [2:0] WR_ENA rw — Internal. Only to be used through TI provided API.
0x228C FSM_ACC_PP — Internal. Only to be used through TI provided API.
0x2290 FSM_ACC_EP — Internal. Only to be used through TI provided API.
  [31:16] RESERVED16 — Internal. Only to be used through TI provided API.
  [15:0] ACC_EP — Internal. Only to be used through TI provided API.
0x22A0 FSM_ADDR — Internal. Only to be used through TI provided API.
  [31] RESERVED31 — Internal. Only to be used through TI provided API.
  [30:28] BANK — Internal. Only to be used through TI provided API.
  [27:0] CUR_ADDR — Internal. Only to be used through TI provided API.
0x22A4 FSM_SECTOR access per field reset 0xFFFF0000 — Internal. Only to be used through TI provided API.
  [31:16] SECT_ERASED rw — Internal. Only to be used through TI provided API.
  [15:8] FSM_SECTOR_EXTENSION ro — Internal. Only to be used through TI provided API.
  [7:4] SECTOR ro — Internal. Only to be used through TI provided API.
  [3:0] SEC_OUT ro — Internal. Only to be used through TI provided API.
0x22A8 FMC_REV_ID — Internal. Only to be used through TI provided API.
  [31:12] MOD_VERSION — Internal. Only to be used through TI provided API.
  [11:0] CONFIG_CRC — Internal. Only to be used through TI provided API.
0x22AC FSM_ERR_ADDR — Internal. Only to be used through TI provided API.
  [31] RESERVED31 — Internal. Only to be used through TI provided API.
  [30:28] FSM_ERR_BANK — Internal. Only to be used through TI provided API.
  [27:24] RESERVED24 — Internal. Only to be used through TI provided API.
  [23:0] FSM_ERR_ADDR — Internal. Only to be used through TI provided API.
0x22B0 FSM_PGM_MAXPUL — Internal. Only to be used through TI provided API.
  [31:12] RESERVED12 — Internal. Only to be used through TI provided API.
  [11:0] FSM_PGM_MAXPUL — Internal. Only to be used through TI provided API.
0x22B4 FSM_EXECUTE access per field reset 0xA000A — Internal. Only to be used through TI provided API.
  [31:20] RESERVED20 ro — Internal. Only to be used through TI provided API.
  [19:16] SUSPEND_NOW rw — Internal. Only to be used through TI provided API.
  [15:5] RESERVED5 ro — Internal. Only to be used through TI provided API.
  [4:0] FSMEXECUTE rw — Internal. Only to be used through TI provided API.
0x22B8 EEPROM_CFG rw reset 0x10000 — Internal. Only to be used through TI provided API.
  [31:0] AUTOSTART_GRACE
0x22C0 FSM_SECTOR1 rw reset 0xFFFFFFFF — Internal. Only to be used through TI provided API.
0x22C4 FSM_SECTOR2 rw reset 0xFFF — Internal. Only to be used through TI provided API.
0x22E0 FSM_BSLE0 rw — Internal. Only to be used through TI provided API.
0x22E4 FSM_BSLE1 rw — Internal. Only to be used through TI provided API.
0x22F0 FSM_BSLP0 rw — Internal. Only to be used through TI provided API.
0x22F4 FSM_BSLP1 rw — Internal. Only to be used through TI provided API.
0x22F8 FSM_PGM128 access per field — FMC FSM Enable 128-bit Wide Programming
  [0] EN_PGM128 rw — 1: Enables 128-bit wide programming. This mode requires programming supply voltage to be greater than 2.5v at the Flash Pump. The primary use case for this mode is manufacturing test for test time reduction. 0: 64-bit wide programming. Valid at any programming voltage. A 128-bit word is divided into two 64-bit words for programming. [default] This register is write protected with the FSM_WR_ENA register.
0x22FC FSM_EN_PRL_BNK_RD access per field — FMC FSM Enable Parallell Reads for Multibanks
  [0] EN_PRL_BNK_RD rw — 1: Enables parallel reads of multiple banks The primary use case for this mode is manufacturing test for test time reduction. 0: Read of one bank only. [default] This register is write protected with the FSM_WR_ENA register.
0x2400 FCFG_BANK reset 0x802 — Internal. Only to be used through TI provided API.
  [31:20] EE_BANK_WIDTH — Internal. Only to be used through TI provided API.
  [19:16] EE_NUM_BANK — Internal. Only to be used through TI provided API.
  [15:4] MAIN_BANK_WIDTH — Internal. Only to be used through TI provided API.
  [3:0] MAIN_NUM_BANK — Internal. Only to be used through TI provided API.
0x2404 FCFG_WRAPPER reset 0x50009007 — Internal. Only to be used through TI provided API.
  [31:24] FAMILY_TYPE — Internal. Only to be used through TI provided API.
  [23:21] RESERVED21 — Internal. Only to be used through TI provided API.
  [20] MEM_MAP — Internal. Only to be used through TI provided API.
  [19:16] CPU2 — Internal. Only to be used through TI provided API.
  [15:12] EE_IN_MAIN — Internal. Only to be used through TI provided API.
  [11] ROM — Internal. Only to be used through TI provided API.
  [10] IFLUSH — Internal. Only to be used through TI provided API.
  [9] SIL3 — Internal. Only to be used through TI provided API.
  [8] ECCA — Internal. Only to be used through TI provided API.
  [7:6] AUTO_SUSP — Internal. Only to be used through TI provided API.
  [5:4] UERR — Internal. Only to be used through TI provided API.
  [3:0] CPU_TYPE1 — Internal. Only to be used through TI provided API.
0x2408 FCFG_BNK_TYPE reset 0x44 — Internal. Only to be used through TI provided API.
  [4n+3:4n] B{n}_TYPE (n=0..7) — Internal. Only to be used through TI provided API.
0x2410 FCFG_B0_START reset 0x2000000 — Internal. Only to be used through TI provided API.
  [31:28] B0_MAX_SECTOR — Internal. Only to be used through TI provided API.
  [27:24] B0_MUX_FACTOR — Internal. Only to be used through TI provided API.
  [23:0] B0_START_ADDR — Internal. Only to be used through TI provided API.
0x2414 FCFG_B1_START reset 0x2058000 — Internal. Only to be used through TI provided API.
  [31:28] B1_MAX_SECTOR — Internal. Only to be used through TI provided API.
  [27:24] B1_MUX_FACTOR — Internal. Only to be used through TI provided API.
  [23:0] B1_START_ADDR — Internal. Only to be used through TI provided API.
{0x2410+4i} FCFG_B{i}_START (i=2..7) — Internal. Only to be used through TI provided API.
  [31:28] B{i}_MAX_SECTOR — Internal. Only to be used through TI provided API.
  [27:24] B{i}_MUX_FACTOR — Internal. Only to be used through TI provided API.
  [23:0] B{i}_START_ADDR — Internal. Only to be used through TI provided API.
0x2430 FCFG_B0_SSIZE0 reset 0x2C0008 — Internal. Only to be used through TI provided API.
  [31:28] RESERVED28 — Internal. Only to be used through TI provided API.
  [27:16] B0_NUM_SECTORS — Internal. Only to be used through TI provided API.
  [15:4] RESERVED4 — Internal. Only to be used through TI provided API.
  [3:0] B0_SECT_SIZE — Internal. Only to be used through TI provided API.
{0x2434+0x10*i} FCFG_B{i}_SSIZE1 (i=0..7) — Internal. Only to be used through TI provided API.
  [31:0] RESERVED
{0x2438+0x10*i} FCFG_B{i}_SSIZE2 (i=0..7) — Internal. Only to be used through TI provided API.
  [31:0] RESERVED
{0x243C+0x10*i} FCFG_B{i}_SSIZE3 (i=0..7) — Internal. Only to be used through TI provided API.
  [31:0] RESERVED
0x2440 FCFG_B1_SSIZE0 reset 0x2C0008 — Internal. Only to be used through TI provided API.
  fields as FCFG_B0_SSIZE0
0x2450 FCFG_B2_SSIZE0 — Internal. Only to be used through TI provided API.
  fields as FCFG_B0_SSIZE0
{0x2430+0x10*i} FCFG_B{i}_SSIZE0 (i=3..7) — Internal. Only to be used through TI provided API.
  [31:0] B{i}_SECT_SIZE
